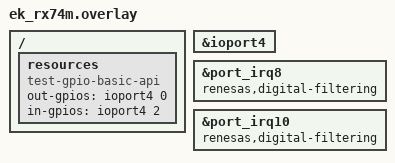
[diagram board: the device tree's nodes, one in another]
/*
 * Copyright (c) 2025 Renesas Electronics Corporation.
 *
 * SPDX-License-Identifier: Apache-2.0
 */

/ {
	resources {
		compatible = "test-gpio-basic-api";
		out-gpios = <&ioport4 0 0>;
		in-gpios = <&ioport4 2 0>;
	};
};

&ioport4 {
	status = "okay";
};

&port_irq8 {
	status = "okay";
	renesas,digital-filtering;
};

&port_irq10 {
	status = "okay";
	renesas,digital-filtering;
};
